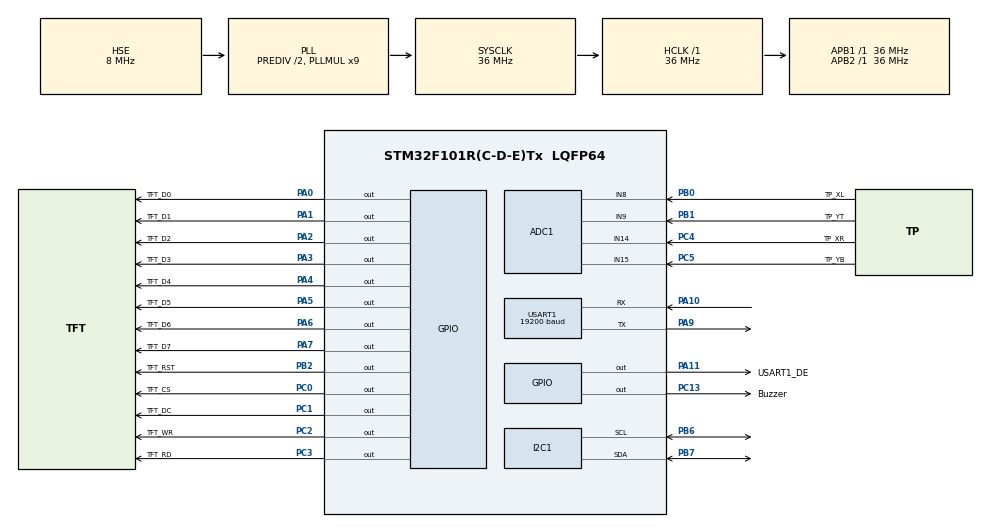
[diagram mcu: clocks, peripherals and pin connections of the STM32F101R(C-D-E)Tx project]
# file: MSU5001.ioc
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ADC1.Channel-0\#ChannelRegularConversion=ADC_CHANNEL_9
ADC1.NbrOfConversionFlag=1
ADC1.Rank-0\#ChannelRegularConversion=1
ADC1.SamplingTime-0\#ChannelRegularConversion=ADC_SAMPLETIME_1CYCLE_5
ADC1.master=1
Mcu.Family=STM32F1
Mcu.Name=STM32F101R(C-D-E)Tx
Mcu.Package=LQFP64
NVIC.ADC1_IRQn=true\:0\:0\:false
NVIC.I2C1_ER_IRQn=true\:0\:0\:false
NVIC.I2C1_EV_IRQn=true\:0\:0\:false
NVIC.PriorityGroup=NVIC_PRIORITYGROUP_4
NVIC.USART1_IRQn=true\:0\:0\:false
PA0-WKUP.GPIO_Label=TFT_D0
PA0-WKUP.GPIO_ModeDefaultOutputPP=GPIO_MODE_OUTPUT_PP
PA0-WKUP.GPIO_Speed=GPIO_SPEED_HIGH
PA0-WKUP.Signal=GPIO_Output
PA1.GPIO_Label=TFT_D1
PA1.GPIO_ModeDefaultOutputPP=GPIO_MODE_OUTPUT_PP
PA1.GPIO_Speed=GPIO_SPEED_HIGH
PA1.Signal=GPIO_Output
PA10.Mode=Asynchronous
PA10.Signal=USART1_RX
PA11.GPIO_Label=USART1_DE
PA11.GPIO_ModeDefaultOutputPP=GPIO_MODE_OUTPUT_PP
PA11.GPIO_Speed=GPIO_SPEED_LOW
PA11.Signal=GPIO_Output
PA2.GPIO_Label=TFT_D2
PA2.GPIO_ModeDefaultOutputPP=GPIO_MODE_OUTPUT_PP
PA2.GPIO_Speed=GPIO_SPEED_HIGH
PA2.Signal=GPIO_Output
PA3.GPIO_Label=TFT_D3
PA3.GPIO_ModeDefaultOutputPP=GPIO_MODE_OUTPUT_PP
PA3.GPIO_Speed=GPIO_SPEED_HIGH
PA3.Signal=GPIO_Output
PA4.GPIO_Label=TFT_D4
PA4.GPIO_ModeDefaultOutputPP=GPIO_MODE_OUTPUT_PP
PA4.GPIO_Speed=GPIO_SPEED_HIGH
PA4.Signal=GPIO_Output
PA5.GPIO_Label=TFT_D5
PA5.GPIO_ModeDefaultOutputPP=GPIO_MODE_OUTPUT_PP
PA5.GPIO_Speed=GPIO_SPEED_HIGH
PA5.Signal=GPIO_Output
PA6.GPIO_Label=TFT_D6
PA6.GPIO_ModeDefaultOutputPP=GPIO_MODE_OUTPUT_PP
PA6.GPIO_Speed=GPIO_SPEED_HIGH
PA6.Signal=GPIO_Output
PA7.GPIO_Label=TFT_D7
PA7.GPIO_ModeDefaultOutputPP=GPIO_MODE_OUTPUT_PP
PA7.GPIO_Speed=GPIO_SPEED_HIGH
PA7.Signal=GPIO_Output
PA9.Mode=Asynchronous
PA9.Signal=USART1_TX
PB0.GPIO_Label=TP_XL
PB0.GPIO_Mode=GPIO_MODE_ANALOG
PB0.Signal=ADCx_IN8
PB1.GPIO_Label=TP_YT
PB1.GPIO_Mode=GPIO_MODE_ANALOG
PB1.Signal=ADCx_IN9
PB2.GPIO_Label=TFT_RST
PB2.GPIO_ModeDefaultOutputPP=GPIO_MODE_OUTPUT_PP
PB2.GPIO_Speed=GPIO_SPEED_HIGH
PB2.Signal=GPIO_Output
PB6.Mode=I2C
PB6.Signal=I2C1_SCL
PB7.Mode=I2C
PB7.Signal=I2C1_SDA
PC0.GPIO_Label=TFT_CS
PC0.GPIO_ModeDefaultOutputPP=GPIO_MODE_OUTPUT_PP
PC0.GPIO_Speed=GPIO_SPEED_HIGH
PC0.Signal=GPIO_Output
PC1.GPIO_Label=TFT_DC
PC1.GPIO_ModeDefaultOutputPP=GPIO_MODE_OUTPUT_PP
PC1.GPIO_Speed=GPIO_SPEED_HIGH
PC1.Signal=GPIO_Output
PC13-TAMPER-RTC.GPIO_Label=Buzzer
PC13-TAMPER-RTC.GPIO_ModeDefaultOutputPP=GPIO_MODE_OUTPUT_PP
PC13-TAMPER-RTC.GPIO_Speed=GPIO_SPEED_LOW
PC13-TAMPER-RTC.Signal=GPIO_Output
PC2.GPIO_Label=TFT_WR
PC2.GPIO_ModeDefaultOutputPP=GPIO_MODE_OUTPUT_PP
PC2.GPIO_Speed=GPIO_SPEED_HIGH
PC2.Signal=GPIO_Output
PC3.GPIO_Label=TFT_RD
PC3.GPIO_ModeDefaultOutputPP=GPIO_MODE_OUTPUT_PP
PC3.GPIO_Speed=GPIO_SPEED_HIGH
PC3.Signal=GPIO_Output
PC4.GPIO_Label=TP_XR
PC4.GPIO_Mode=GPIO_MODE_ANALOG
PC4.Signal=ADCx_IN14
PC5.GPIO_Label=TP_YB
PC5.GPIO_Mode=GPIO_MODE_ANALOG
PC5.Signal=ADCx_IN15
PD0-OSC_IN.Mode=HSE-External-Oscillator
PD0-OSC_IN.Signal=RCC_OSC_IN
PD1-OSC_OUT.Mode=HSE-External-Oscillator
PD1-OSC_OUT.Signal=RCC_OSC_OUT
ProjectManager.TargetToolchain=EWARM
RCC.ADCPresc=RCC_ADCPCLK2_DIV4
RCC.AHBFreq_Value=36000000
RCC.APB1Freq_Value=36000000
RCC.APB1TimFreq_Value=36000000
RCC.APB2Freq_Value=36000000
RCC.EnbaleCSS=true
RCC.HCLKFreq_Value=36000000
RCC.HSEDivPLL=RCC_HSE_PREDIV_DIV2
RCC.HSIState=RCC_HSI_ON
RCC.PLLMUL=RCC_PLL_MUL9
RCC.PLLSourceVirtual=RCC_PLLSOURCE_HSE
RCC.SYSCLKFreq_VALUE=36000000
RCC.SYSCLKSource=RCC_SYSCLKSOURCE_PLLCLK
SH.ADCx_IN14.0=ADC1_IN14,IN14
SH.ADCx_IN15.0=ADC1_IN15,IN15
SH.ADCx_IN8.0=ADC1_IN8,IN8
SH.ADCx_IN9.0=ADC1_IN9,IN9
USART1.BaudRate=19200
VP_ADC1_TempSens_Input.Mode=IN-TempSens
VP_CRC_VS_CRC.Mode=CRC_Activate
VP_IWDG_VS_IWDG.Mode=IWDG_Activate
VP_WWDG_VS_WWDG.Mode=WWDG_Activate
board=MSU5001

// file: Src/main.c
/**
  ******************************************************************************
  * File Name          : main.c
  * Description        : Main program body
  ******************************************************************************
  *
  * COPYRIGHT(c) 2015 STMicroelectronics
  *
  * Redistribution and use in source and binary forms, with or without modification,
  * are permitted provided that the following conditions are met:
  *   1. Redistributions of source code must retain the above copyright notice,
  *      this list of conditions and the following disclaimer.
  *   2. Redistributions in binary form must reproduce the above copyright notice,
  *      this list of conditions and the following disclaimer in the documentation
  *      and/or other materials provided with the distribution.
  *   3. Neither the name of STMicroelectronics nor the names of its contributors
  *      may be used to endorse or promote products derived from this software
  *      without specific prior written permission.
  *
  * THIS SOFTWARE IS PROVIDED BY THE COPYRIGHT HOLDERS AND CONTRIBUTORS "AS IS"
  * AND ANY EXPRESS OR IMPLIED WARRANTIES, INCLUDING, BUT NOT LIMITED TO, THE
  * IMPLIED WARRANTIES OF MERCHANTABILITY AND FITNESS FOR A PARTICULAR PURPOSE ARE
  * DISCLAIMED. IN NO EVENT SHALL THE COPYRIGHT HOLDER OR CONTRIBUTORS BE LIABLE
  * FOR ANY DIRECT, INDIRECT, INCIDENTAL, SPECIAL, EXEMPLARY, OR CONSEQUENTIAL
  * DAMAGES (INCLUDING, BUT NOT LIMITED TO, PROCUREMENT OF SUBSTITUTE GOODS OR
  * SERVICES; LOSS OF USE, DATA, OR PROFITS; OR BUSINESS INTERRUPTION) HOWEVER
  * CAUSED AND ON ANY THEORY OF LIABILITY, WHETHER IN CONTRACT, STRICT LIABILITY,
  * OR TORT (INCLUDING NEGLIGENCE OR OTHERWISE) ARISING IN ANY WAY OUT OF THE USE
  * OF THIS SOFTWARE, EVEN IF ADVISED OF THE POSSIBILITY OF SUCH DAMAGE.
  *
  ******************************************************************************
  */
#include "stm32f1xx_hal.h"

/* USER CODE BEGIN Includes */
#include "GUI.h"
/* USER CODE END Includes */

ADC_HandleTypeDef hadc1;

CRC_HandleTypeDef hcrc;

I2C_HandleTypeDef hi2c1;

IWDG_HandleTypeDef hiwdg;

UART_HandleTypeDef huart1;

WWDG_HandleTypeDef hwwdg;

/* USER CODE BEGIN PV */
/* Private variables ---------------------------------------------------------*/

/* USER CODE END PV */

void SystemClock_Config(void);
static void MX_GPIO_Init(void);
static void MX_ADC1_Init(void);
static void MX_CRC_Init(void);
static void MX_I2C1_Init(void);
static void MX_IWDG_Init(void);
static void MX_USART1_UART_Init(void);
static void MX_WWDG_Init(void);

/* USER CODE BEGIN PFP */
/* Private function prototypes -----------------------------------------------*/

/* USER CODE END PFP */

int main(void)
{

  /* MCU Configuration----------------------------------------------------------*/

  /* Reset of all peripherals, Initializes the Flash interface and the Systick. */
  HAL_Init();

  /* Configure the system clock */
  SystemClock_Config();

  /* Initialize all configured peripherals */
  MX_GPIO_Init();
  MX_ADC1_Init();
  MX_CRC_Init();
  MX_I2C1_Init();
  MX_IWDG_Init();
  MX_USART1_UART_Init();
  MX_WWDG_Init();

  /* USER CODE BEGIN 2 */
  GUI_Init();
  GUI_DispString("Hello world!");
  /* USER CODE END 2 */

  /* Infinite loop */
  while (1)
  {

  /* USER CODE BEGIN 3 */
    HAL_GPIO_TogglePin(GPIOC, GPIO_PIN_13);
    HAL_Delay(1000); // �������� 1 ���
  }
  /* USER CODE END 3 */

}

/** System Clock Configuration
*/
void SystemClock_Config(void)
{

  RCC_OscInitTypeDef RCC_OscInitStruct;
  RCC_ClkInitTypeDef RCC_ClkInitStruct;
  RCC_PeriphCLKInitTypeDef PeriphClkInit;

  RCC_OscInitStruct.OscillatorType = RCC_OSCILLATORTYPE_LSI|RCC_OSCILLATORTYPE_HSE;
  RCC_OscInitStruct.HSEState = RCC_HSE_ON;
  RCC_OscInitStruct.HSEPredivValue = RCC_HSE_PREDIV_DIV2;
  RCC_OscInitStruct.LSIState = RCC_LSI_ON;
  RCC_OscInitStruct.PLL.PLLState = RCC_PLL_ON;
  RCC_OscInitStruct.PLL.PLLSource = RCC_PLLSOURCE_HSE;
  RCC_OscInitStruct.PLL.PLLMUL = RCC_PLL_MUL9;
  HAL_RCC_OscConfig(&RCC_OscInitStruct);

  RCC_ClkInitStruct.ClockType = RCC_CLOCKTYPE_SYSCLK;
  RCC_ClkInitStruct.SYSCLKSource = RCC_SYSCLKSOURCE_PLLCLK;
  RCC_ClkInitStruct.AHBCLKDivider = RCC_SYSCLK_DIV1;
  RCC_ClkInitStruct.APB1CLKDivider = RCC_HCLK_DIV1;
  RCC_ClkInitStruct.APB2CLKDivider = RCC_HCLK_DIV1;
  HAL_RCC_ClockConfig(&RCC_ClkInitStruct, FLASH_LATENCY_1);

  PeriphClkInit.PeriphClockSelection = RCC_PERIPHCLK_ADC;
  PeriphClkInit.AdcClockSelection = RCC_ADCPCLK2_DIV4;
  HAL_RCCEx_PeriphCLKConfig(&PeriphClkInit);

  HAL_RCC_EnableCSS();

  HAL_SYSTICK_Config(HAL_RCC_GetHCLKFreq()/1000);

  HAL_SYSTICK_CLKSourceConfig(SYSTICK_CLKSOURCE_HCLK);

}

/* ADC1 init function */
void MX_ADC1_Init(void)
{

  ADC_ChannelConfTypeDef sConfig;

    /**Common config
    */
  hadc1.Instance = ADC1;
  hadc1.Init.ScanConvMode = ADC_SCAN_DISABLE;
  hadc1.Init.ContinuousConvMode = DISABLE;
  hadc1.Init.DiscontinuousConvMode = DISABLE;
  hadc1.Init.ExternalTrigConv = ADC_SOFTWARE_START;
  hadc1.Init.DataAlign = ADC_DATAALIGN_RIGHT;
  hadc1.Init.NbrOfConversion = 1;
  HAL_ADC_Init(&hadc1);

    /**Configure Regular Channel
    */
  sConfig.Channel = ADC_CHANNEL_9;
  sConfig.Rank = 1;
  sConfig.SamplingTime = ADC_SAMPLETIME_1CYCLE_5;
  HAL_ADC_ConfigChannel(&hadc1, &sConfig);

}

/* CRC init function */
void MX_CRC_Init(void)
{

  hcrc.Instance = CRC;
  HAL_CRC_Init(&hcrc);

}

/* I2C1 init function */
void MX_I2C1_Init(void)
{

  hi2c1.Instance = I2C1;
  hi2c1.Init.ClockSpeed = 100000;
  hi2c1.Init.DutyCycle = I2C_DUTYCYCLE_2;
  hi2c1.Init.OwnAddress1 = 0;
  hi2c1.Init.AddressingMode = I2C_ADDRESSINGMODE_7BIT;
  hi2c1.Init.DualAddressMode = I2C_DUALADDRESS_DISABLED;
  hi2c1.Init.OwnAddress2 = 0;
  hi2c1.Init.GeneralCallMode = I2C_GENERALCALL_DISABLED;
  hi2c1.Init.NoStretchMode = I2C_NOSTRETCH_DISABLED;
  HAL_I2C_Init(&hi2c1);

}

/* IWDG init function */
void MX_IWDG_Init(void)
{

  hiwdg.Instance = IWDG;
  hiwdg.Init.Prescaler = IWDG_PRESCALER_4;
  hiwdg.Init.Reload = 4095;
  HAL_IWDG_Init(&hiwdg);

}

/* USART1 init function */
void MX_USART1_UART_Init(void)
{

  huart1.Instance = USART1;
  huart1.Init.BaudRate = 19200;
  huart1.Init.WordLength = UART_WORDLENGTH_8B;
  huart1.Init.StopBits = UART_STOPBITS_1;
  huart1.Init.Parity = UART_PARITY_NONE;
  huart1.Init.Mode = UART_MODE_TX_RX;
  huart1.Init.HwFlowCtl = UART_HWCONTROL_NONE;
  huart1.Init.OverSampling = UART_OVERSAMPLING_16;
  HAL_UART_Init(&huart1);

}

/* WWDG init function */
void MX_WWDG_Init(void)
{

  hwwdg.Instance = WWDG;
  hwwdg.Init.Prescaler = WWDG_PRESCALER_1;
  hwwdg.Init.Window = 64;
  hwwdg.Init.Counter = 64;
  HAL_WWDG_Init(&hwwdg);

}

/** Configure pins as
        * Analog
        * Input
        * Output
        * EVENT_OUT
        * EXTI
*/
void MX_GPIO_Init(void)
{

  GPIO_InitTypeDef GPIO_InitStruct;

  /* GPIO Ports Clock Enable */
  __GPIOC_CLK_ENABLE();
  __GPIOD_CLK_ENABLE();
  __GPIOA_CLK_ENABLE();
  __GPIOB_CLK_ENABLE();

  /*Configure GPIO pin : PC13 */
  GPIO_InitStruct.Pin = GPIO_PIN_13;
  GPIO_InitStruct.Mode = GPIO_MODE_OUTPUT_PP;
  GPIO_InitStruct.Speed = GPIO_SPEED_LOW;
  HAL_GPIO_Init(GPIOC, &GPIO_InitStruct);

  /*Configure GPIO pins : PC0 PC1 PC2 PC3 */
  GPIO_InitStruct.Pin = GPIO_PIN_0|GPIO_PIN_1|GPIO_PIN_2|GPIO_PIN_3;
  GPIO_InitStruct.Mode = GPIO_MODE_OUTPUT_PP;
  GPIO_InitStruct.Speed = GPIO_SPEED_HIGH;
  HAL_GPIO_Init(GPIOC, &GPIO_InitStruct);

  /*Configure GPIO pins : PA0 PA1 PA2 PA3
                           PA4 PA5 PA6 PA7 */
  GPIO_InitStruct.Pin = GPIO_PIN_0|GPIO_PIN_1|GPIO_PIN_2|GPIO_PIN_3
                          |GPIO_PIN_4|GPIO_PIN_5|GPIO_PIN_6|GPIO_PIN_7;
  GPIO_InitStruct.Mode = GPIO_MODE_OUTPUT_PP;
  GPIO_InitStruct.Speed = GPIO_SPEED_HIGH;
  HAL_GPIO_Init(GPIOA, &GPIO_InitStruct);

  /*Configure GPIO pin : PB2 */
  GPIO_InitStruct.Pin = GPIO_PIN_2;
  GPIO_InitStruct.Mode = GPIO_MODE_OUTPUT_PP;
  GPIO_InitStruct.Speed = GPIO_SPEED_HIGH;
  HAL_GPIO_Init(GPIOB, &GPIO_InitStruct);

  /*Configure GPIO pin : PA11 */
  GPIO_InitStruct.Pin = GPIO_PIN_11;
  GPIO_InitStruct.Mode = GPIO_MODE_OUTPUT_PP;
  GPIO_InitStruct.Speed = GPIO_SPEED_LOW;
  HAL_GPIO_Init(GPIOA, &GPIO_InitStruct);

}

/************************ (C) COPYRIGHT STMicroelectronics *****END OF FILE****/
